# M0Plus register map
File version: 1.0
Registers are 32-bit, read-write, reset 0x0 unless marked. A register's access mark holds for its fields unless they carry their own. Offsets are from the block's base; lines under a group give offsets from that group; [hi:lo] are bit positions; {n}, {i} and the like mark numbered series; 'fields as' and 'values as' point back to an identical list; <NAME> marks a mode.

## Memory map
0xE000E000 NVIC blocks up to offset 0xD28 — Registers group

## NVIC — Registers group
Base 0xE000E000
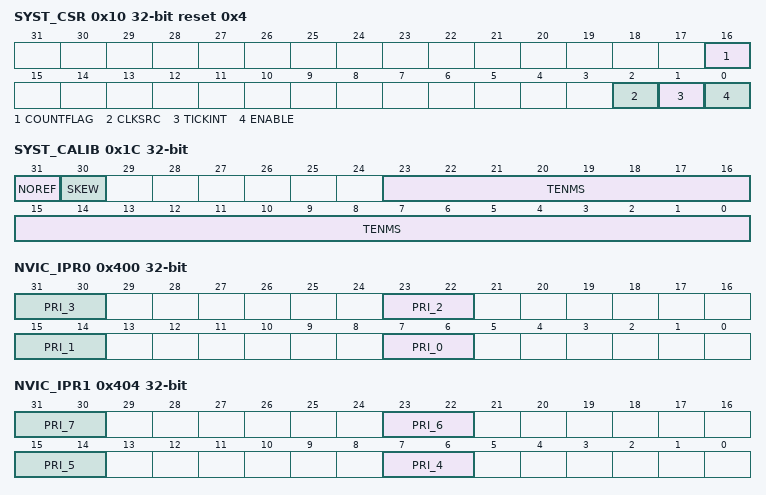
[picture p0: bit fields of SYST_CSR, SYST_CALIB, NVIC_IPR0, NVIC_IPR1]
0x10 SYST_CSR reset 0x4 (reset mask 0xFFFFFFFB) — SysTick Control and Status
  [16] COUNTFLAG ro read-modifies — Returns 1 if timer counted to 0 since last time this register was read. COUNTFLAG is set by a count transition from 1 to 0. COUNTFLAG is cleared on read or by a write to the Current Value register.
  [2] CLKSRC — 1 : core clock used for SysTick. 0 : clock source is (optional) external reference clock
  [1] TICKINT — 1 : counting down to 0 will cause the SysTick exception to be pended. Clearing the SysTick Current Value register by a register write in software will not cause SysTick to be pended. 0 : counting down to 0 does not cause the SysTick exception to be pended. Software can use COUNTFLAG to determine if a count to zero has occurred.
  [0] ENABLE — 1 : the counter will operate in a multi-shot manner. 0 : the counter is disabled
0x14 SYST_RVR reset not defined — SysTick Reload value
  [23:0] RELOAD — Value to load into the Current Value register when the counter reaches 0.
0x18 SYST_CVR reset not defined — SysTick Current value
  [23:0] CURRENT — Current counter value. This is the value of the counter at the time it is sampled. The counter does not provide read-modify-write protection. The register is write-clear. A software write of any value will clear the register to 0. Unsupported bits RAZ (see SysTick Reload Value register).
0x1C SYST_CALIB reset not defined — SysTick Calibration Value Register
  [31] NOREF — Indicates whether the IMPLEMENTATION DEFINED reference clock is provided: When this bit is 1, the CLKSOURCE bit of the SYST_CSR register is forced to 1 and cannot be cleared to 0.
  [30] SKEW — Indicates whether the 10ms calibration value is exact: 0 10ms calibration value is exact. 1 10ms calibration value is inexact, because of the clock frequency.
  [23:0] TENMS — Optionally, holds a reload value to be used for 10ms (100Hz) timing, subject to system clock skew errors. If this field is zero, the calibration value is not known.
0x100 NVIC_ISER — IRQ0 ~ IRQ31 Set-Enable Control Register
  [31:0] SETENA write-1-sets — Enable one or more interrupts within a group of 32. Each bit represents an interrupt number from IRQ0 ~ IRQ31 (Vector number from 16 ~ 47). Writing 1 will enable the associated interrupt. Writing 0 has no effect. The register reads back with the current enable state.
0x180 NVIC_ICER — IRQ0 ~ IRQ31 Clear-Enable Control Register
  [31:0] CLRENA write-1-clears — Disable one or more interrupts within a group of 32. Each bit represents an interrupt number from IRQ0 ~ IRQ31 (Vector number from 16 ~ 47). Writing 1 will disable the associated interrupt. Writing 0 has no effect. The register reads back with the current enable state.
0x200 NVIC_ISPR — IRQ0 ~ IRQ31 Set-Pending Control Register
  [31:0] SETPEND write-1-sets — Writing 1 to a bit pends the associated interrupt under software control. Each bit represents an interrupt number from IRQ0 ~ IRQ31 (Vector number from 16 ~ 47). Writing 0 has no effect. The register reads back with the current pending state.
0x280 NVIC_ICPR — IRQ0 ~ IRQ31 Clear-Pending Control Register
  [31:0] CLRPEND write-1-clears — Writing 1 to a bit un-pends the associated interrupt under software control. Each bit represents an interrupt number from IRQ0 ~ IRQ31 (Vector number from 16 ~ 47). Writing 0 has no effect. The register reads back with the current pending state.
0x400 NVIC_IPR0 — IRQ0 ~ IRQ3 Priority Control Register
  [8n+7:8n+6] PRI_{n} (n=0..3) — Priority of IRQ{n} "0" denotes the highest priority and "3" denotes lowest priority
0x404 NVIC_IPR1 — IRQ4 ~ IRQ7 Priority Control Register
  [8n-25:8n-26] PRI_{n} (n=4..7) — Priority of IRQ{n} "0" denotes the highest priority and "3" denotes lowest priority
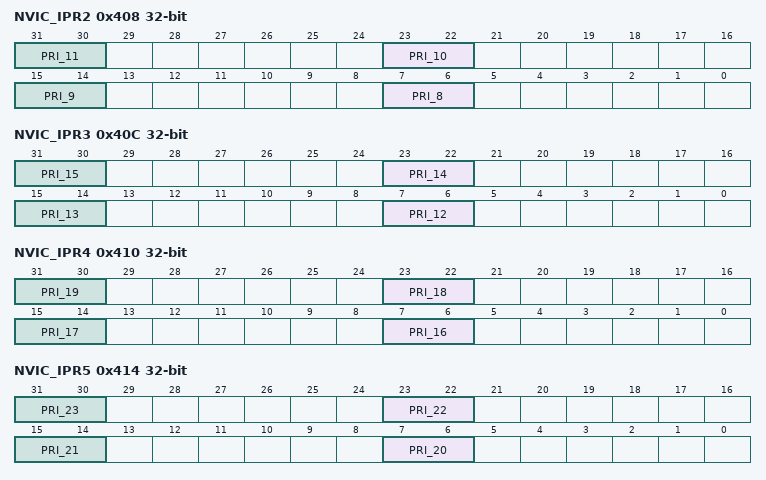
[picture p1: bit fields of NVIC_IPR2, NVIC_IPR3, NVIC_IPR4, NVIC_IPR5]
0x408 NVIC_IPR2 — IRQ8 ~ IRQ11 Priority Control Register
  [8n-57:8n-58] PRI_{n} (n=8..11) — Priority of IRQ{n} "0" denotes the highest priority and "3" denotes lowest priority
0x40C NVIC_IPR3 — IRQ12 ~ IRQ15 Priority Control Register
  [8n-89:8n-90] PRI_{n} (n=12..15) — Priority of IRQ{n} "0" denotes the highest priority and "3" denotes lowest priority
0x410 NVIC_IPR4 — IRQ16 ~ IRQ19 Priority Control Register
  [8n-121:8n-122] PRI_{n} (n=16..19) — Priority of IRQ{n} "0" denotes the highest priority and "3" denotes lowest priority
0x414 NVIC_IPR5 — IRQ20 ~ IRQ23 Priority Control Register
  [8n-153:8n-154] PRI_{n} (n=20..23) — Priority of IRQ{n} "0" denotes the highest priority and "3" denotes lowest priority
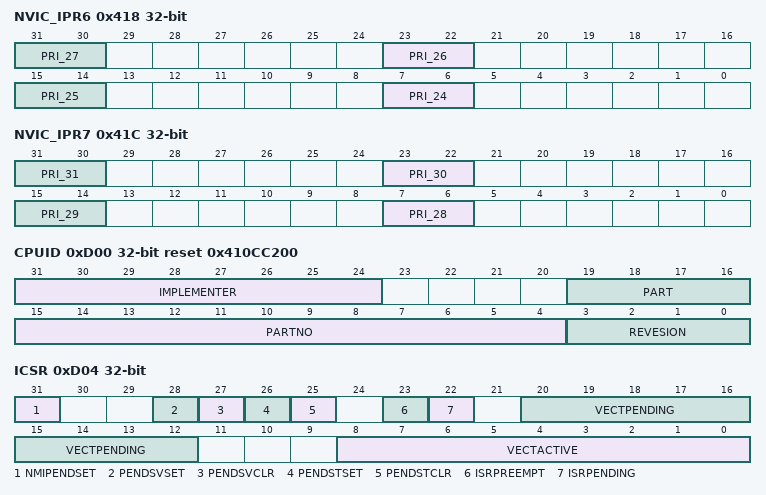
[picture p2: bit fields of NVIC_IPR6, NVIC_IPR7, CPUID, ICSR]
0x418 NVIC_IPR6 — IRQ24 ~ IRQ27 Priority Control Register
  [8n-185:8n-186] PRI_{n} (n=24..27) — Priority of IRQ{n} "0" denotes the highest priority and "3" denotes lowest priority
0x41C NVIC_IPR7 — IRQ28 ~ IRQ31 Priority Control Register
  [8n-217:8n-218] PRI_{n} (n=28..31) — Priority of IRQ{n} "0" denotes the highest priority and "3" denotes lowest priority
0xD00 CPUID ro reset 0x410CC200
  [31:24] IMPLEMENTER — Implementer code assigned by ARM. ( ARM = 0x41)
  [19:16] PART — Reads as 0xC for ARMv6-M parts
  [15:4] PARTNO — Reads as 0xC20
  [3:0] REVESION — Reads as 0x0
0xD04 ICSR — Interrupt Control State Register
  [31] NMIPENDSET — Setting this bit will activate an NMI. Since NMI is the highest priority exception, it will activate as soon as it is registered. Reads back with current state (1 if Pending, 0 if not).
  [28] PENDSVSET — Set a pending PendSV interrupt. This is normally used to request a context switch. Reads back with current state (1 if Pending, 0 if not).
  [27] PENDSVCLR wo — Write 1 to clear a pending PendSV interrupt. This is a write only bit.
  [26] PENDSTSET — Set a pending SysTick. Reads back with current state (1 if Pending, 0 if not).
  [25] PENDSTCLR wo — Write 1 to clear a pending SysTick. This is a write only bit.
  [23] ISRPREEMPT ro — If set, a pending exception will be serviced on exit from the debug halt state. This is a read only bit.
  [22] ISRPENDING ro — Indicates if an external configurable (NVIC generated) interrupt is pending. This is a read only bit.
  [20:12] VECTPENDING ro — Indicates the exception number for the highest priority pending exception. The pending state includes the effect of memory-mapped enable and mask registers. It does not include the PRIMASK special-purpose register qualifier. A value of zero indicates no pending exceptions. This is a read only bit.
  [8:0] VECTACTIVE ro — 0 = Thread mode Value > 1 = the exception number for the current executing exception.This is a read only bit.
0xD08 VTOR — Vector Table Offset Register
  [30:7] TBLOFF — Table offset address
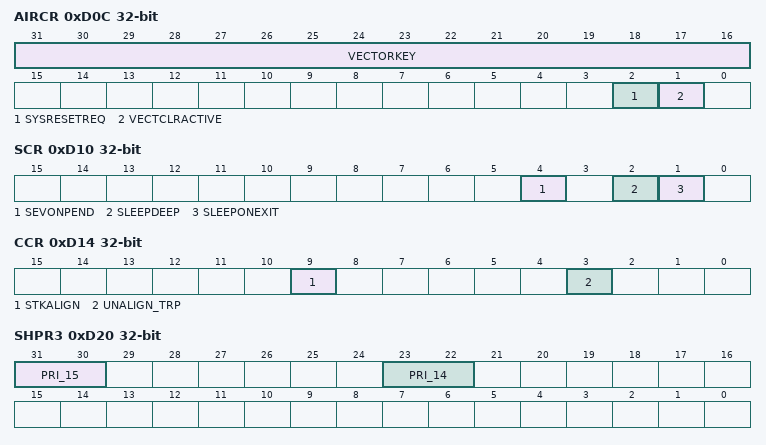
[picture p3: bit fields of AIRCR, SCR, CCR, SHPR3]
0xD0C AIRCR — Application Interrupt and Reset Control Register
  [31:16] VECTORKEY — When write this register, this field should be 0x05FA, otherwise the write action will be unpredictable.
  [2] SYSRESETREQ wo — Writing this bit 1 will cause a reset signal to be asserted to the chip to indicate a reset is requested. The bit is a write only bit and self-clears as part of the reset sequence.
  [1] VECTCLRACTIVE wo — Set this bit to 1 will clears all active state information for fixed and configurable exceptions. The bit is a write only bit and can only be written when the core is halted. Note: It is the debugger's responsibility to re-initialize the stack.
0xD10 SCR — System Control Register
  [4] SEVONPEND — When enabled, interrupt transitions from Inactive to Pending are included in the list of wakeup events for the WFE instruction.
  [2] SLEEPDEEP — A qualifying hint that indicates waking from sleep might take longer.
  [1] SLEEPONEXIT — When set to 1, the core can enter a sleep state on an exception return to Thread mode. This is the mode and exception level entered at reset, the base level of execution.
0xD14 CCR — Configuration and Control Register
  [9] STKALIGN — On exception entry, the SP used prior to the exception is adjusted to be 8-byte aligned and the context to restore it is saved. The SP is restored on the associated exception return.
  [3] UNALIGN_TRP — unaligned word and halfword accesses generate a HardFault exception.
0xD1C SHPR2 — System Handler Priority Register 2
  [31:30] PRI_11 — Priority of system handler 11 SVCall "0" denotes the highest priority and "3" denotes lowest priority
0xD20 SHPR3 — System Handler Priority Register 3
  [31:30] PRI_15 — Priority of system handler 15 SysTick "0" denotes the highest priority and "3" denotes lowest priority
  [23:22] PRI_14 — Priority of system handler 14 PendSV "0" denotes the highest priority and "3" denotes lowest priority
0xD24 SHCSR — System Handler Control and State Register
  [15] SVCALLPENDED — This bit reflects the pending state on a read, and updates the pending state, to the value written, on a write
